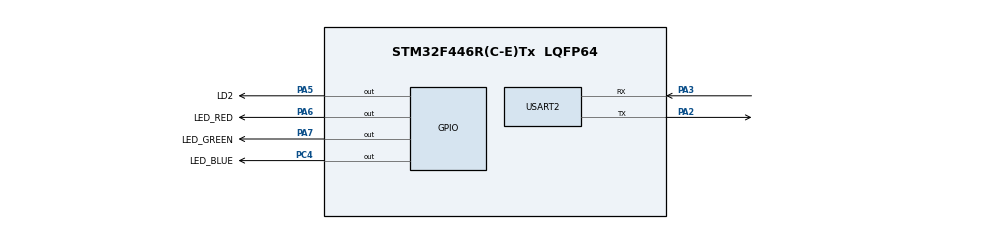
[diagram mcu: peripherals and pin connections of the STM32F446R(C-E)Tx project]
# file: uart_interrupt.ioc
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Dma.Request0=USART2_RX
Dma.Request1=USART2_TX
Dma.USART2_RX.0.Direction=DMA_PERIPH_TO_MEMORY
Dma.USART2_RX.0.FIFOMode=DMA_FIFOMODE_DISABLE
Dma.USART2_RX.0.Instance=DMA1_Stream5
Dma.USART2_RX.0.MemDataAlignment=DMA_MDATAALIGN_BYTE
Dma.USART2_RX.0.MemInc=DMA_MINC_ENABLE
Dma.USART2_RX.0.Mode=DMA_NORMAL
Dma.USART2_RX.0.PeriphDataAlignment=DMA_PDATAALIGN_BYTE
Dma.USART2_RX.0.PeriphInc=DMA_PINC_DISABLE
Dma.USART2_RX.0.Priority=DMA_PRIORITY_LOW
Dma.USART2_TX.1.Direction=DMA_MEMORY_TO_PERIPH
Dma.USART2_TX.1.FIFOMode=DMA_FIFOMODE_DISABLE
Dma.USART2_TX.1.Instance=DMA1_Stream6
Dma.USART2_TX.1.MemDataAlignment=DMA_MDATAALIGN_BYTE
Dma.USART2_TX.1.MemInc=DMA_MINC_ENABLE
Dma.USART2_TX.1.Mode=DMA_NORMAL
Dma.USART2_TX.1.PeriphDataAlignment=DMA_PDATAALIGN_BYTE
Dma.USART2_TX.1.PeriphInc=DMA_PINC_DISABLE
Dma.USART2_TX.1.Priority=DMA_PRIORITY_LOW
Mcu.Family=STM32F4
Mcu.Name=STM32F446R(C-E)Tx
Mcu.Package=LQFP64
NVIC.DMA1_Stream5_IRQn=true\:0\:0\:false\:false\:true\:false\:true\:true
NVIC.DMA1_Stream6_IRQn=true\:0\:0\:false\:false\:true\:false\:true\:true
NVIC.PriorityGroup=NVIC_PRIORITYGROUP_4
NVIC.USART2_IRQn=true\:0\:0\:false\:false\:true\:true\:true\:true
PA2.Mode=Asynchronous
PA2.Signal=USART2_TX
PA3.Mode=Asynchronous
PA3.Signal=USART2_RX
PA5.GPIO_Label=LD2
PA5.Signal=GPIO_Output
PA6.GPIO_Label=LED_RED
PA6.Signal=GPIO_Output
PA7.GPIO_Label=LED_GREEN
PA7.Signal=GPIO_Output
PC4.GPIO_Label=LED_BLUE
PC4.Signal=GPIO_Output
ProjectManager.HeapSize=0x200
ProjectManager.StackSize=0x400
ProjectManager.TargetToolchain=STM32CubeIDE
RCC.CortexFreq_Value=16000000
RCC.USBFreq_Value=96000000
RCC.VCOOutputFreq_Value=192000000
USART2.VirtualMode=VM_ASYNC
board=custom

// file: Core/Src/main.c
/* USER CODE BEGIN Header */
/**
  ******************************************************************************
  * @file           : main.c
  * @brief          : Main program body
  ******************************************************************************
  * @attention
  *
  * Copyright (c) 2024 STMicroelectronics.
  * All rights reserved.
  *
  * This software is licensed under terms that can be found in the LICENSE file
  * in the root directory of this software component.
  * If no LICENSE file comes with this software, it is provided AS-IS.
  *
  ******************************************************************************
  */
/* USER CODE END Header */
#include "main.h"

/* USER CODE BEGIN Includes */
#include "string.h"
/* USER CODE END Includes */

UART_HandleTypeDef huart2;
DMA_HandleTypeDef hdma_usart2_rx;
DMA_HandleTypeDef hdma_usart2_tx;

/* USER CODE BEGIN PV */
#define RX_BUFF_SIZE 256
uint8_t rx_buff[RX_BUFF_SIZE];
/* USER CODE END PV */

void SystemClock_Config(void);
static void MX_GPIO_Init(void);
static void MX_DMA_Init(void);
static void MX_USART2_UART_Init(void);

/* USER CODE BEGIN 0 */
void HAL_UARTEx_RxEventCallback(UART_HandleTypeDef *huart, uint16_t Size){	//HAL_UARTEx_ReceiveToIdle_DMA對應的callback函數，Size是實際上我們所接收的數據長度(並非RX_BUFF_SIZE)。
	if(huart == &huart2){	//用來確認是哪個usart接口所引起的中斷(沒寫也可運行)
		if ( (rx_buff[Size-1] == 0x0A) && (rx_buff[Size-2] == 0x0D))	//判斷所傳送的不定長數據中，結尾的兩個字分別為\r(0x0D, CR, Carriage Return)以及\n(0x0A, LF, Line Feed)
			{
				uint8_t tx_buff[20] = "OK";
				HAL_UART_Transmit_DMA(&huart2, tx_buff, sizeof(tx_buff));	//向電腦發送OK字串
				// reset buffer index
				memset(rx_buff, 0x00, RX_BUFF_SIZE);	//清空傳送的數據(沒寫也可運行)
			}
	}
	HAL_UARTEx_ReceiveToIdle_DMA(&huart2, rx_buff, sizeof(rx_buff));
	__HAL_DMA_DISABLE_IT(&hdma_usart2_rx, DMA_IT_HT);
}
/* USER CODE END 0 */

int main(void)
{

  /* MCU Configuration--------------------------------------------------------*/

  /* Reset of all peripherals, Initializes the Flash interface and the Systick. */
  HAL_Init();

  /* Configure the system clock */
  SystemClock_Config();

  /* Initialize all configured peripherals */
  MX_GPIO_Init();
  MX_DMA_Init();
  MX_USART2_UART_Init();
  /* USER CODE BEGIN 2 */
  HAL_UARTEx_ReceiveToIdle_DMA(&huart2, rx_buff, sizeof(rx_buff));	//當串口接收由忙碌轉成空閒(Idle)時會觸發，可用來接收不定長數據。
  __HAL_DMA_DISABLE_IT(&hdma_usart2_rx, DMA_IT_HT);		//在DMA模式下，數據傳送一半時也會執行中斷一次，需關閉此中斷DMA_IT_HT
  /* USER CODE END 2 */

  /* Infinite loop */
  while (1)
  {

  }
}

void SystemClock_Config(void)
{
  RCC_OscInitTypeDef RCC_OscInitStruct = {0};
  RCC_ClkInitTypeDef RCC_ClkInitStruct = {0};

  /** Configure the main internal regulator output voltage
  */
  __HAL_RCC_PWR_CLK_ENABLE();
  __HAL_PWR_VOLTAGESCALING_CONFIG(PWR_REGULATOR_VOLTAGE_SCALE3);

  /** Initializes the RCC Oscillators according to the specified parameters
  * in the RCC_OscInitTypeDef structure.
  */
  RCC_OscInitStruct.OscillatorType = RCC_OSCILLATORTYPE_HSI;
  RCC_OscInitStruct.HSIState = RCC_HSI_ON;
  RCC_OscInitStruct.HSICalibrationValue = RCC_HSICALIBRATION_DEFAULT;
  RCC_OscInitStruct.PLL.PLLState = RCC_PLL_NONE;
  if (HAL_RCC_OscConfig(&RCC_OscInitStruct) != HAL_OK)
  {
    Error_Handler();
  }

  /** Initializes the CPU, AHB and APB buses clocks
  */
  RCC_ClkInitStruct.ClockType = RCC_CLOCKTYPE_HCLK|RCC_CLOCKTYPE_SYSCLK
                              |RCC_CLOCKTYPE_PCLK1|RCC_CLOCKTYPE_PCLK2;
  RCC_ClkInitStruct.SYSCLKSource = RCC_SYSCLKSOURCE_HSI;
  RCC_ClkInitStruct.AHBCLKDivider = RCC_SYSCLK_DIV1;
  RCC_ClkInitStruct.APB1CLKDivider = RCC_HCLK_DIV1;
  RCC_ClkInitStruct.APB2CLKDivider = RCC_HCLK_DIV1;

  if (HAL_RCC_ClockConfig(&RCC_ClkInitStruct, FLASH_LATENCY_0) != HAL_OK)
  {
    Error_Handler();
  }
}

static void MX_USART2_UART_Init(void)
{

  huart2.Instance = USART2;
  huart2.Init.BaudRate = 115200;
  huart2.Init.WordLength = UART_WORDLENGTH_8B;
  huart2.Init.StopBits = UART_STOPBITS_1;
  huart2.Init.Parity = UART_PARITY_NONE;
  huart2.Init.Mode = UART_MODE_TX_RX;
  huart2.Init.HwFlowCtl = UART_HWCONTROL_NONE;
  huart2.Init.OverSampling = UART_OVERSAMPLING_16;
  if (HAL_UART_Init(&huart2) != HAL_OK)
  {
    Error_Handler();
  }

}

static void MX_DMA_Init(void)
{

  /* DMA controller clock enable */
  __HAL_RCC_DMA1_CLK_ENABLE();

  /* DMA interrupt init */
  /* DMA1_Stream5_IRQn interrupt configuration */
  HAL_NVIC_SetPriority(DMA1_Stream5_IRQn, 0, 0);
  HAL_NVIC_EnableIRQ(DMA1_Stream5_IRQn);
  /* DMA1_Stream6_IRQn interrupt configuration */
  HAL_NVIC_SetPriority(DMA1_Stream6_IRQn, 0, 0);
  HAL_NVIC_EnableIRQ(DMA1_Stream6_IRQn);

}

static void MX_GPIO_Init(void)
{
  GPIO_InitTypeDef GPIO_InitStruct = {0};

  /* GPIO Ports Clock Enable */
  __HAL_RCC_GPIOA_CLK_ENABLE();
  __HAL_RCC_GPIOC_CLK_ENABLE();

  /*Configure GPIO pin Output Level */
  HAL_GPIO_WritePin(GPIOA, LD2_Pin|LED_RED_Pin|LED_GREEN_Pin, GPIO_PIN_RESET);

  /*Configure GPIO pin Output Level */
  HAL_GPIO_WritePin(LED_BLUE_GPIO_Port, LED_BLUE_Pin, GPIO_PIN_RESET);

  /*Configure GPIO pins : LD2_Pin LED_RED_Pin LED_GREEN_Pin */
  GPIO_InitStruct.Pin = LD2_Pin|LED_RED_Pin|LED_GREEN_Pin;
  GPIO_InitStruct.Mode = GPIO_MODE_OUTPUT_PP;
  GPIO_InitStruct.Pull = GPIO_NOPULL;
  GPIO_InitStruct.Speed = GPIO_SPEED_FREQ_LOW;
  HAL_GPIO_Init(GPIOA, &GPIO_InitStruct);

  /*Configure GPIO pin : LED_BLUE_Pin */
  GPIO_InitStruct.Pin = LED_BLUE_Pin;
  GPIO_InitStruct.Mode = GPIO_MODE_OUTPUT_PP;
  GPIO_InitStruct.Pull = GPIO_NOPULL;
  GPIO_InitStruct.Speed = GPIO_SPEED_FREQ_LOW;
  HAL_GPIO_Init(LED_BLUE_GPIO_Port, &GPIO_InitStruct);

}

void Error_Handler(void)
{
  __disable_irq();
  while (1)
  {
  }
}
